# MEC1705Q register map
Vendor: Microchip Technology; Series: MEC1705; File version: 0
CPU: CM4 r1p0, little endian, MPU, FPU, 3 interrupt priority bits, 156 interrupts
Registers are 32-bit, read-write, reset 0x0 unless marked. A register's access mark holds for its fields unless they carry their own. Offsets are from the block's base; [hi:lo] are bit positions; {n}, {i} and the like mark numbered series; 'fields as' and 'values as' point back to an identical list.

## ACPI_EC0 — The ACPI Embedded Controller Interface (ACPI-ECI) provides a four byte full duplex data interface which is a superset of the standard ACPI Embedded Controller Interface (ACPI-ECI) one byte data interface. The ACPI Embedded Controller Interface (ACPI-ECI) defaults to the standard one byte interface.
Base 0x400F0800; register names take the prefix ACPI_EC_
Same registers: ACPI_EC1 0x400F0C00, ACPI_EC2 0x400F1000, ACPI_EC3 0x400F1400, ACPI_EC4 0x400F1800
{0x0+i} OS_DATA[{i}] (i=0..3) 8-bit — This is byte n of the 32-bit ACPI-OS DATA BYTES[3:0]. Writes by the ACPI_OS to the ACPI-OS DATA BYTES[n] are aliased to the OS2EC DATA BYTES[n]. Reads by the ACPI_OS from the ACPI-OS DATA BYTES[n] are aliased to the EC2OS DATA BYTES[n].
0x04 OS_CMD 8-bit wo — Writes to the this register are aliased in the OS2EC Data EC Byte 0 Register. Writes to this register also set the CMD and IBF bits in the OS STATUS OS Register
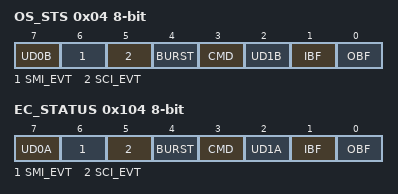
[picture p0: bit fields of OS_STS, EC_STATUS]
0x04 OS_STS 8-bit ro — OS STATUS
  [7] UD0B — User Defined
  [6] SMI_EVT — This bit is set when an SMI event is pending; i.e., the ACPI_EC is requesting an SMI query; This bit is cleared when no SMI events are pending. This bit is an ACPI_EC-maintained software flag that is set when the ACPI_EC has detected an internal event that requires system management interrupt handler attention. The ACPI_EC sets this bit before generating an SMI.
  [5] SCI_EVT — This bit is set by software when an SCI event is pending; i.e., the ACPI_EC is requesting an SCI query; SCI Event flag is clear when no SCI events are pending. This bit is an ACPI_EC-maintained software flag that is set when the embedded controller has detected an internal event that requires operating system attention. The ACPI_EC sets this bit before generating an SCI to the OS.
  [4] BURST — The BURST bit is set when the ACPI_EC is in Burst Mode for polled command processing; the BURST bit is cleared when the. ACPI_EC is in Normal mode for interrupt-driven command processing. The BURST bit is is an ACPI_EC-maintained software flag that indicates the embedded controller has received the Burst Enable command from the host, has halted normal processing, and is waiting for a series of commands to be sent from the host.
  [3] CMD — This bit is set when the OS2EC Data EC Byte 0 Register contains a command byte written into ACPI OS COMMAND Register; this bit is cleared when the OS2EC DATA BYTES[3:0] contains a data byte written into the ACPI-OS DATA BYTES[3:0]. This bit is hardware controlled: ACPI_OS writes to any of the four ACPI-OS DATA BYTES[3:0] bytes clears this bit. ACPI_OS writes to the ACPI OS COMMAND Register sets this bit. Note: This bit allows the embedded controller to differentiate the start of a command sequence from a data byte write operation.
  [2] UD1B — User Defined
  [1] IBF — The Input Buffer Full bit is set to indicate that a the ACPI_OS has written a command or data to the ACPI_EC and that data is ready. This bit is automatically cleared when data has been read by the ACPI_EC. Note: The setting and clearing of this IBF varies depending on the setting of the following bits: CMD bit in this register and FOUR_BYTE_ACCESS bit in the OS Byte Control Register.
  [0] OBF — The Output Buffer Full bit is set to indicate that a the ACPI_EC has written a data to the ACPI_OS and that data is ready. This bit is automatically cleared when all the data has been read by the ACPI_OS. Note: The setting and clearing of this OBF varies depending on the setting FOUR_BYTE_ACCESS bit in the OS Byte Control Register.
0x05 OS_BYTE_CTRL 8-bit ro — OS Byte Control Register
  [0] FOUR_BYTE_ACCESS — When this bit is set to '1', the ACPI Embedded Controller Interface (ACPI-ECI) accesses four bytes through the. ACPI-OS DATA BYTES[3:0]. When this bit is cleared to '0', the ACPI Embedded Controller Interface (ACPI-ECI) accesses one byte through the ACPI OS Data Register Byte 0 Register. This corresponds to Legacy Mode. This bit effects the behaviour of the IBF and OBF bits in the OS STATUS OS Register.
{0x100+i} EC2OS_DATA[{i}] (i=0..3) 8-bit — This is byte n of the 32-bit EC2OS DATA BYTES[3:0]. Writes by the ACPI_EC to the EC2OS DATA BYTES[3:0] are aliased to the. ACPI-OS DATA BYTES[3:0].
0x104 EC_STATUS 8-bit
  [7] UD0A — User Defined
  [6] SMI_EVT — This bit is set when an SMI event is pending
  [5] SCI_EVT — This bit is set by software when an SCI event is pending
  [4] BURST — The BURST bit is set when the ACPI_EC is in Burst Mode
  [3] CMD — This bit is set when the OS2EC Data EC Byte 0 Register contains a command byte written into ACPI OS COMMAND Register
  [2] UD1A — UD1A User Defined
  [1] IBF — The Input Buffer Full bit is set to indicate that a the ACPI_OS has written a command or data to the ACPI_EC and that data is ready.
  [0] OBF — The Output Buffer Full bit is set to indicate that a the ACPI_EC has written a data to the ACPI_OS and that data is ready.
0x105 EC_BYTE_CTRL 8-bit — Byte Control EC-Register
  fields as OS_BYTE_CTRL
{0x108+i} OS2EC_DATA[{i}] (i=0..3) 8-bit — OS_TO_EC_DATA_BYTE_n. This is byte n of the 32-bit OS2EC DATA BYTES[3:0]. When the CMD bit in the OS STATUS OS Register is cleared to '0', reads by the ACPI_EC from the OS2EC DATA BYTES[3:0] are aliased to the ACPI-OS DATA BYTES[3:0].

## Notices in the file
Copyright (c) 2023 Microchip Technology Inc.
SPDX-License-Identifier: Apache-2.0
Licensed under the Apache License, Version 2.0 (the "License");
you may not use this file except in compliance with the License.
You may obtain a copy of the License at
http://www.apache.org/licenses/LICENSE-2.0
Unless required by applicable law or agreed to in writing, software
distributed under the License is distributed on an "AS IS" BASIS,
WITHOUT WARRANTIES OR CONDITIONS OF ANY KIND, either express or implied.
See the License for the specific language governing permissions and
limitations under the License.
